# AC7842x register map
Vendor: AutoChips; Series: AC78; File version: 1.0
CPU: CM4 r0p1, little endian, MPU, FPU, VTOR, 4 interrupt priority bits
Registers are 32-bit, read-write, reset 0x0 unless marked. A register's access mark holds for its fields unless they carry their own. Offsets are from the block's base; [hi:lo] are bit positions; {n}, {i} and the like mark numbered series; 'fields as' and 'values as' point back to an identical list.

## CRC — CRC Cyclic redundancy check
Base 0x40084000
0x00 DATA reset 0xFFFFFFFF
  [31:0] DATA — Load Data or Seed
0x04 POLY reset 0x1021
  [31:0] POLY — Load Polynomial
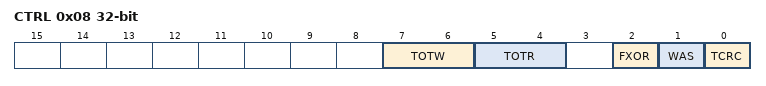
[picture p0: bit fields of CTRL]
0x08 CTRL — Control Register
  [7:6] TOTW — Type Of Transpose For Write Check Data
    0=No Transposition; 1=Only bits in bytes are transposed; 2=Both bits in bytes and bytes are transposed; 3=Only bytes are transposed
  [5:4] TOTR — Type Of Transpose For Read Check Result
    values as TOTW
  [2] FXOR — Complement Read Of CRC Check Result
    0=No XOR on reading value of the CRC Data register; 1=Invert or complement the read value of the CRC Data register
  [1] WAS — Decide Load Data or Seed
    0=Write data values; 1=Write seed values
  [0] TCRC — 16 or 32 CRC Type
    0=16-bit CRC protocol; 1=32-bit CRC protocol

## EIM_CTRL — GLB_EN
Base 0x40088000
0x00 EIM_GLB_ENABLE — EIM global enable
  [0] GLB_EN — EIM global enable control
    0=EIM global disabled; 1=EIM global enabled
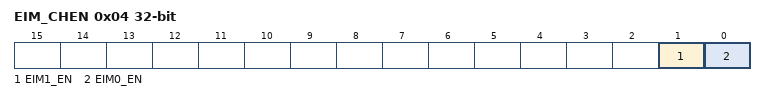
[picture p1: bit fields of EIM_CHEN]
0x04 EIM_CHEN reset not defined — EIM channel enable control
  [1] EIM1_EN — EIM channel1 enable control
    0=EIM channel1 disabled; 1=EIM channel1 enabled
  [0] EIM0_EN — EIM channel0 enable control
    0=EIM channel0 disabled; 1=EIM channel0 enabled

## EIM_CHANNEL0 — SRAM Error Injection Bit Control
Base 0x40088010
Same registers: EIM_CHANNEL1 0x40088080
0x00 EIM_INJ_DATA — SRAM data injection control
  [31:0] EIM0_DATA_INJ — Each bit control related data bit inversed or not
0x04 EIM_INJ_ADDR — SRAM address injection control
  [14:0] EIM_ADDR_INJ — Each bit control related address bit inversed or not
0x08 EIM_INJ_ECC — SRAM ECC code injection control
  [6:0] EIM_ECC_INJ — Each bit control related ECC bit inversed or not

## ECC_SRAM — SRAM Error ctrl
Base 0x40088100
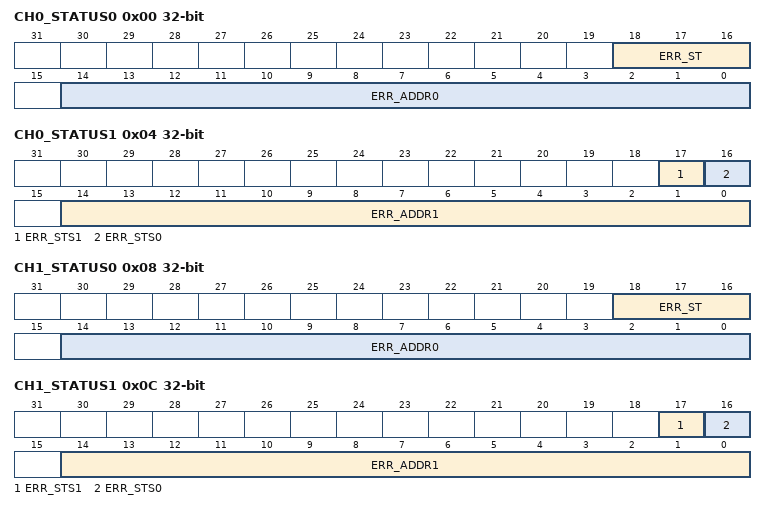
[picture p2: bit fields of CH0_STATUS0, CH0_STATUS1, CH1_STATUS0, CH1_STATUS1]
0x00 CH0_STATUS0 ro — SRAM ECC CH0 status and addr0 register
  [18:16] ERR_ST — ECC (2/1)bit error status
    0=ECC has no error; 1=ECC 2 bit error is active; 2=ECC 1 bit error at bit38 is active; 3=ECC 1 bit error at bit[37:0] is active; 0b1xx=ECC address error is active
  [14:0] ERR_ADDR0 — ECC CH0 1bit error addr
0x04 CH0_STATUS1 ro — ECC CH0 2bit error addr
  [17] ERR_STS1 — ECC CH0 2bit Error interrupt status
    0=no 2bit error; 1=2bit error occured
  [16] ERR_STS0 — ECC CH0 1bit Error interrupt status
    0=no 1bit error; 1=1bit error occured
  [14:0] ERR_ADDR1 — ECC CH0 2bit Error Address
0x08 CH1_STATUS0 ro — SRAM ECC CH1 status and addr0 register
  [18:16] ERR_ST — ECC (2/1)bit error status
    values as CH0_STATUS0.ERR_ST
  [14:0] ERR_ADDR0 — ECC CH1 1bit error addr
0x0C CH1_STATUS1 ro — ECC CH1 2bit error addr
  [17] ERR_STS1 — ECC CH1 2bit Error interrupt status
    0=no 2bit error; 1=2bit error occured
  [16] ERR_STS0 — ECC CH1 1bit Error interrupt status
    0=no 1bit error; 1=1bit error occured
  [14:0] ERR_ADDR1 — ECC CH1 2bit Error Address
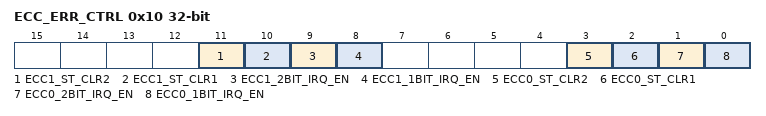
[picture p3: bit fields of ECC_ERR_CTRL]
0x10 ECC_ERR_CTRL reset not defined — ECC Error status control registers
  [11] ECC1_ST_CLR2 — ECC CH1 error and addr status clear
    0=No effect; 1=clear ECC CH1 error and addr status
  [10] ECC1_ST_CLR1 — ECC CH1 interrupt error status clear
    0=No effect; 1=clear ECC CH1 interrupt error status
  [9] ECC1_2BIT_IRQ_EN — ECC CH1 2bit error irq enable ctrl
    0=ECC CH1 2bit error irq disabled; 1=ECC CH1 2bit error irq enabled
  [8] ECC1_1BIT_IRQ_EN — ECC CH1 1bit error irq enable ctrl
    0=ECC CH1 1bit error irq disabled; 1=ECC CH1 1bit error irq enabled
  [3] ECC0_ST_CLR2 — ECC CH0 error and addr status clear
    0=No effect; 1=clear ECC CH0 error and addr status
  [2] ECC0_ST_CLR1 — ECC CH0 interrupt error status clear
    0=No effect; 1=clear ECC CH0 interrupt error status
  [1] ECC0_2BIT_IRQ_EN — ECC CH0 2bit error irq enable ctrl
    0=ECC CH0 2bit error irq disabled; 1=ECC CH0 2bit error irq enabled
  [0] ECC0_1BIT_IRQ_EN — ECC CH0 1bit error irq enable ctrl
    0=ECC CH0 1bit error irq disabled; 1=ECC CH0 1bit error irq enabled

## EWDG — External Watchdog Timer
Base 0x4000B400
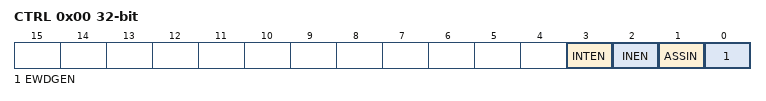
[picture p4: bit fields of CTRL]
0x00 CTRL — Control Register
  [3] INTEN — Interrupt Enable
  [2] INEN — Input Enable
  [1] ASSIN — EWDG's Assertion State Select
  [0] EWDGEN — EWDG enable
0x04 SERV — Service Register
  [7:0] SERVICE
0x08 CMPL — Compare Low Register
  [7:0] COMPAREL
0x0C CMPH reset 0xFF — Compare High Register
  [7:0] COMPAREH
0x10 CLKPRESCALER — Clock Prescaler Register
  [7:0] CLK_DIV

## CMU_VHSI — VHSI Clock Monitor Uint
Base 0x40000800
Same registers: CMU_HSE 0x40000A00, CMU_PLL 0x40000C00
0x00 CR — Configure Register
  [2:0] MONE — Monitor enable
0x04 RCCR reset 0xC8 — Reference Count Configure Register
  [15:0] WINLEN — Reference clock count window length
0x08 HTCR — High Threshold Configure Register
  [23:0] HIGHTHR — The upper count threshold of the monitored clock
0x0C LTCR — Low Threshold Configure Register
  [23:0] LOWTHR — The lower count threshold of the monitored clock
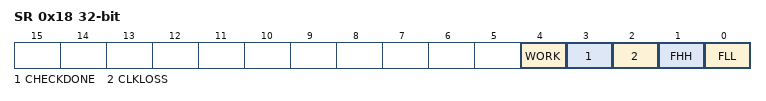
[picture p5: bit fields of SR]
0x18 SR — Status Register
  [4] WORK ro — CMU is currently monitoring the clock or not
    0=Monitor stop; 1=Monitor start
  [3] CHECKDONE ro — check done status flag
  [2] CLKLOSS ro — Clock loss status flag
  [1] FHH — The status flag bit generated after mon_cnt is exceeds than the upper threshold
    0=No FHH event; 1=FHH event occur
  [0] FLL — The status flag bit generated after mon_cnt is less than the lower threshold
    0=No FLL event; 1=FLL event occur
0x1C REFCNT — Reference Count Register
  [15:0] WINLEN — Reference clock count window length
0x20 MONCNT — Monitor Count Register
  [23:0] moncnt — Monitor Count clock

## CSE_PRAM
Base 0x14001000
{0x0+0x10*i} CMD_PG{i}_WORD0 (i=0..7) — Commond page {i} word 0
{0x4+0x10*i} CMD_PG{i}_WORD1 (i=0..7) — Commond page {i} word 1
{0x8+0x10*i} CMD_PG{i}_WORD2 (i=0..7) — Commond page {i} word 2
{0xC+0x10*i} CMD_PG{i}_WORD3 (i=0..7) — Commond page {i} word 3
